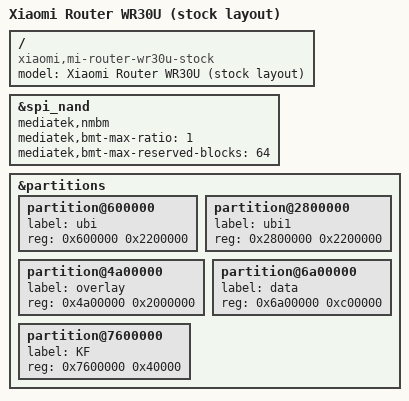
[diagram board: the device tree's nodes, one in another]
// SPDX-License-Identifier: GPL-2.0-or-later OR MIT

/dts-v1/;
#include "mt7981-xiaomi-mi-router-wr30u.dtsi"

/ {
	model = "Xiaomi Router WR30U (stock layout)";
	compatible = "xiaomi,mi-router-wr30u-stock", "mediatek,mt7981";
};

&spi_nand {
	mediatek,nmbm;
	mediatek,bmt-max-ratio = <1>;
	mediatek,bmt-max-reserved-blocks = <64>;
};

&partitions {
	partition@600000 {
		label = "ubi";
		reg = <0x600000 0x2200000>;
	};

	partition@2800000 {
		label = "ubi1";
		reg = <0x2800000 0x2200000>;
	};
	
	partition@4a00000 {
		label = "overlay";
		reg = <0x4a00000 0x2000000>;
	};
	
	partition@6a00000 {
		label = "data";
		reg = <0x6a00000 0xc00000>;
	};
	
	partition@7600000 {
		label = "KF";
		reg = <0x7600000 0x40000>;
	};
};
